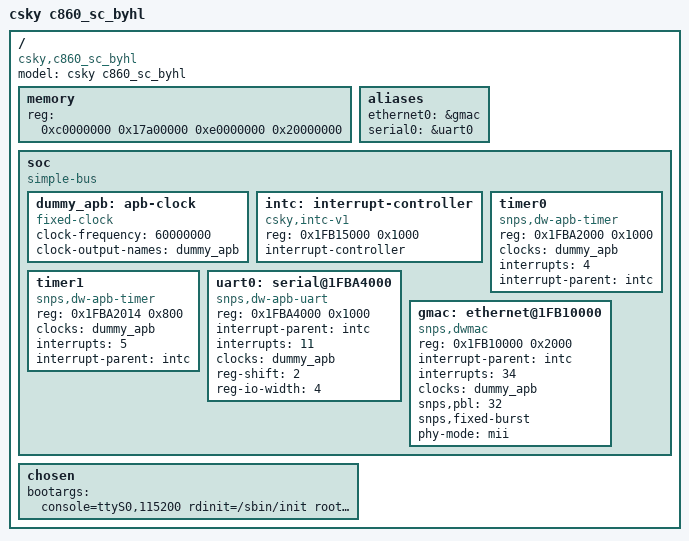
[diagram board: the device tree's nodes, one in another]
/dts-v1/;
//#include <dt-bindings/interrupt-controller/irq.h>
//#include <dt-bindings/gpio/gpio.h>
//#include <dt-bindings/input/input.h>

/ {
	model = "csky c860_sc_byhl";
	compatible = "csky,c860_sc_byhl";
	#address-cells = <1>;
	#size-cells = <1>;

	memory {
		device_type = "memory";
		/*
		 * 0x00000000 - 0x00200000: Reserved for VPU work buf
		 * 0x17c00000 - 0x18000000: Reserved for VPU iram
		 */
		reg = <0xc0000000 0x17a00000 0xe0000000 0x20000000>;
	};

	aliases {
		ethernet0 = &gmac;
		serial0 = &uart0;
	};

	soc {
		#address-cells = <1>;
		#size-cells = <1>;
		compatible = "simple-bus";
		ranges;

		dummy_apb: apb-clock {
			compatible = "fixed-clock";
			clock-frequency = <60000000>;
			clock-output-names = "dummy_apb";
			#clock-cells = <0>;
		};

		intc: interrupt-controller {
			compatible = "csky,intc-v1";
			reg = <0x1FB15000 0x1000>;
			interrupt-controller;
			#interrupt-cells = <1>;
		};

		/* clockevent */
		timer0 {
			compatible = "snps,dw-apb-timer";
			reg = <0x1FBA2000 0x1000>;
			clocks = <&dummy_apb>;
			clock-names = "timer";
			interrupts = <4>;
			interrupt-parent = <&intc>;
		};

		/* clocksource */
		timer1 {
			compatible = "snps,dw-apb-timer";
			reg = <0x1FBA2014 0x800>;
			clocks = <&dummy_apb>;
			clock-names = "timer";
			interrupts = <5>;
			interrupt-parent = <&intc>;
		};

		uart0: serial@1FBA4000 {
			compatible = "snps,dw-apb-uart";
			reg = <0x1FBA4000 0x1000>;
			interrupt-parent = <&intc>;
			interrupts = <11>;
			clocks = <&dummy_apb>;
			clock-names = "baudclk";
			reg-shift = <2>;
			reg-io-width = <4>;
		};

		gmac: ethernet@1FB10000 {
			compatible = "snps,dwmac";
			reg = <0x1FB10000 0x2000>;
			interrupt-parent = <&intc>;
			interrupts = <34>;
			interrupt-names = "macirq";
			clocks = <&dummy_apb>;
			clock-names = "stmmaceth";
			snps,pbl = <32>;
			snps,fixed-burst;
			phy-mode = "mii";
		};
	};

	chosen {
		// bootargs = "console=ttyS0,115200 init=/sbin/init root=/dev/nfs rw nfsroot=172.16.28.184:/home/rtos_nfs/br/rootfs,v3,tcp,nolock ip=172.16.150.100::172.16.150.254:255.255.255.0";
		bootargs = "console=ttyS0,115200 rdinit=/sbin/init root=/dev/ram0 clk_ignore_unused loglevel=7";
	};
};

